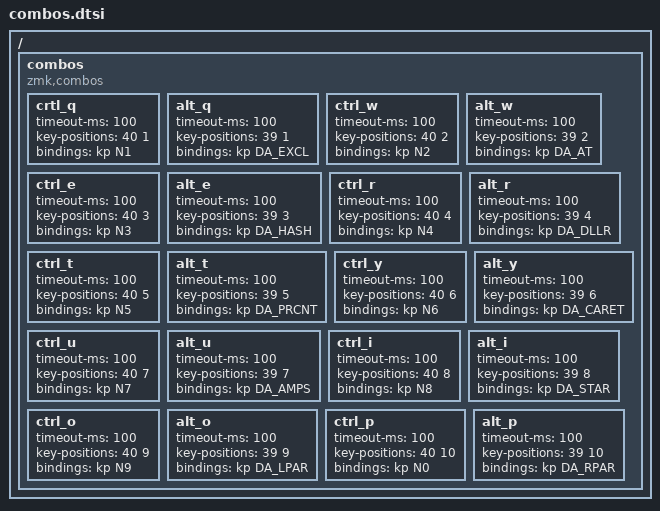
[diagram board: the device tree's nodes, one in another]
/ {
    combos {
        compatible = "zmk,combos";
        crtl_q {
            timeout-ms = <100>;
            key-positions = <40 1>;
            bindings = <&kp N1>;
        };
        alt_q {
            timeout-ms = <100>;
            key-positions = <39 1>;
            bindings = <&kp DA_EXCL>;
        };
                ctrl_w {
            timeout-ms = <100>;
            key-positions = <40 2>;
            bindings = <&kp N2>;
        };
        alt_w {
            timeout-ms = <100>;
            key-positions = <39 2>;
            bindings = <&kp DA_AT>;   // @
        };

        // E (pos 3)
        ctrl_e {
            timeout-ms = <100>;
            key-positions = <40 3>;
            bindings = <&kp N3>;
        };
        alt_e {
            timeout-ms = <100>;
            key-positions = <39 3>;
            bindings = <&kp DA_HASH>;  // #
        };

        // R (pos 4)
        ctrl_r {
            timeout-ms = <100>;
            key-positions = <40 4>;
            bindings = <&kp N4>;
        };
        alt_r {
            timeout-ms = <100>;
            key-positions = <39 4>;
            bindings = <&kp DA_DLLR>;  // $
        };

        // T (pos 5)
        ctrl_t {
            timeout-ms = <100>;
            key-positions = <40 5>;
            bindings = <&kp N5>;
        };
        alt_t {
            timeout-ms = <100>;
            key-positions = <39 5>;
            bindings = <&kp DA_PRCNT>;  // %
        };

        // Y (pos 6)
        ctrl_y {
            timeout-ms = <100>;
            key-positions = <40 6>;
            bindings = <&kp N6>;
        };
        alt_y {
            timeout-ms = <100>;
            key-positions = <39 6>;
            bindings = <&kp DA_CARET>;  // ^
        };

        // U (pos 7)
        ctrl_u {
            timeout-ms = <100>;
            key-positions = <40 7>;
            bindings = <&kp N7>;
        };
        alt_u {
            timeout-ms = <100>;
            key-positions = <39 7>;
            bindings = <&kp DA_AMPS>;  // &
        };

        // I (pos 8)
        ctrl_i {
            timeout-ms = <100>;
            key-positions = <40 8>;
            bindings = <&kp N8>;
        };
        alt_i {
            timeout-ms = <100>;
            key-positions = <39 8>;
            bindings = <&kp DA_STAR>;  // *
        };

        // O (pos 9)
        ctrl_o {
            timeout-ms = <100>;
            key-positions = <40 9>;
            bindings = <&kp N9>;
        };
        alt_o {
            timeout-ms = <100>;
            key-positions = <39 9>;
            bindings = <&kp DA_LPAR>;  // (
        };

        // P (pos 10)
        ctrl_p {
            timeout-ms = <100>;
            key-positions = <40 10>;
            bindings = <&kp N0>;
        };
        alt_p {
            timeout-ms = <100>;
            key-positions = <39 10>;
            bindings = <&kp DA_RPAR>;  // )
        };
    };
};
